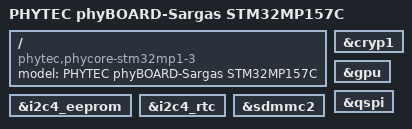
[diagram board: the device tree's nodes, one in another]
// SPDX-License-Identifier: (GPL-2.0+ OR BSD-3-Clause)
/*
 * Copyright (C) Phytec GmbH 2019-2020 - All Rights Reserved
 * Author: Dom VOVARD <dom.vovard@linrt.com>.
 */

/dts-v1/;

#include "stm32mp157.dtsi"
#include "stm32mp15xc.dtsi"
#include "stm32mp15xx-phycore-som.dtsi"
#include "stm32mp15xx-phyboard-sargas.dtsi"

/ {
	model = "PHYTEC phyBOARD-Sargas STM32MP157C";
	compatible = "phytec,phycore-stm32mp1-3",
		     "phytec,phycore-stm32mp157c-som", "st,stm32mp157";
};

&cryp1 {
	status = "okay";
};

&gpu {
	status = "okay";
};

&i2c4_eeprom {
	status = "okay";
};

&i2c4_rtc {
	status = "okay";
};

&qspi {
	status = "okay";
};

&sdmmc2 {
	status = "okay";
};
